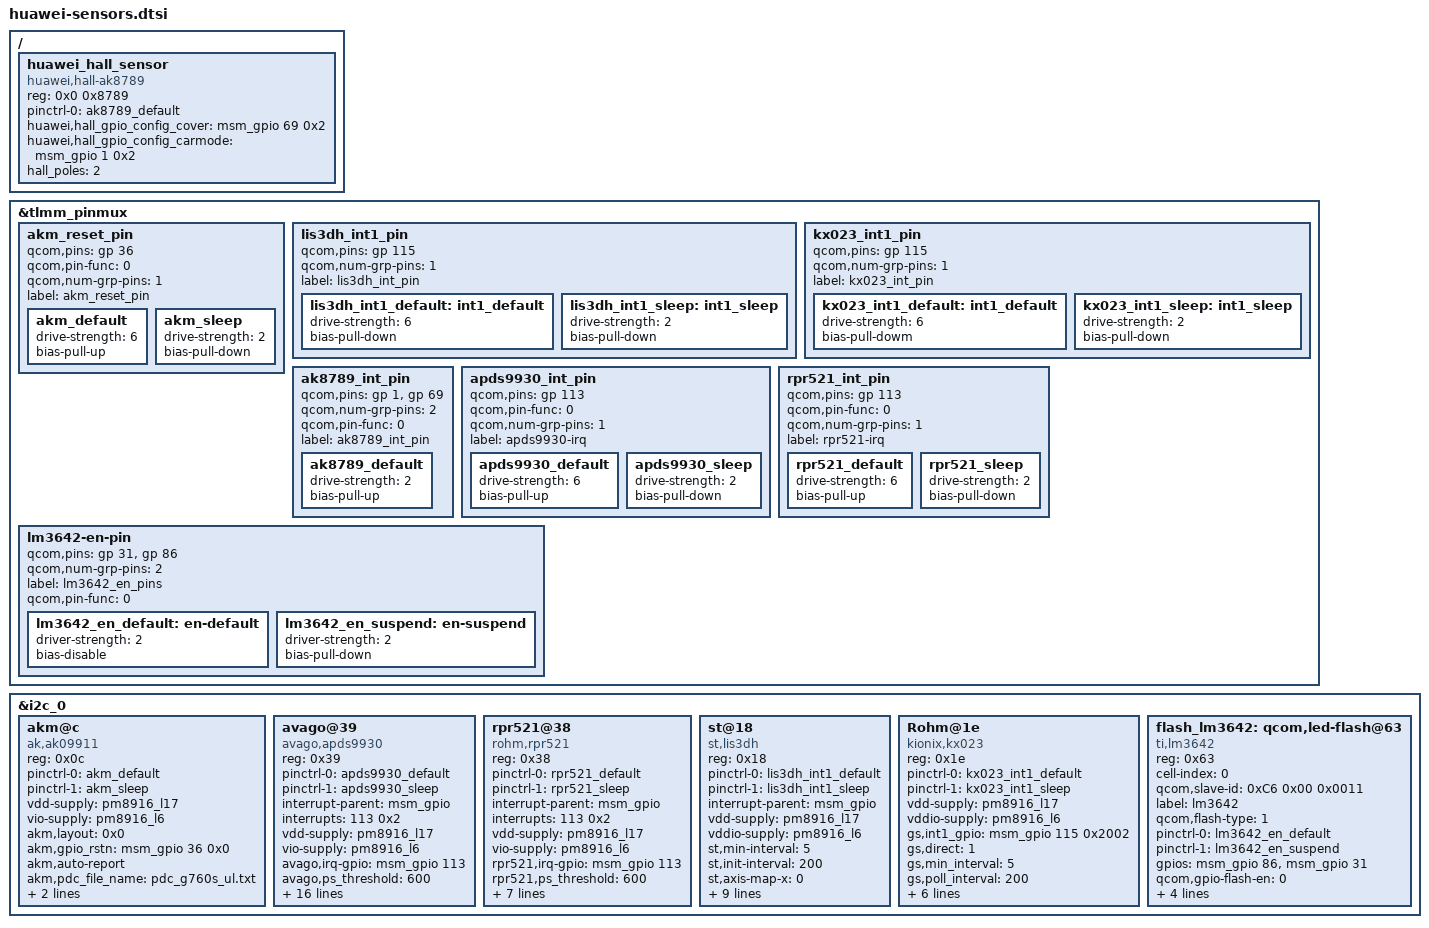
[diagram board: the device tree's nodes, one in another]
/*use fromdos convert file format to linux*/
/* Copyright (c) 2013 The Linux Foundation. All rights reserved.
 *
 * This program is free software; you can redistribute it and/or modify
 * it under the terms of the GNU General Public License version 2 and
 * only version 2 as published by the Free Software Foundation.
 *
 * This program is distributed in the hope that it will be useful,
 * but WITHOUT ANY WARRANTY; without even the implied warranty of
 * MERCHANTABILITY or FITNESS FOR A PARTICULAR PURPOSE.  See the
 * GNU General Public License for more details.
 */
&tlmm_pinmux {
	akm_reset_pin {
		qcom,pins = <&gp 36>;
		qcom,pin-func = <0>;
		qcom,num-grp-pins = <1>;
		label = "akm_reset_pin";
		akm_default: akm_default {
			drive-strength = <6>;
			bias-pull-up;
		};
		akm_sleep: akm_sleep {
			drive-strength = <2>;
			bias-pull-down;
		};
	};

	lis3dh_int1_pin {
		qcom,pins = <&gp 115>;
		qcom,num-grp-pins = <1>;
		label = "lis3dh_int_pin";
		lis3dh_int1_default: int1_default {
			drive-strength = <6>;
			bias-pull-down;
		};
		lis3dh_int1_sleep: int1_sleep {
			drive-strength = <2>;
			bias-pull-down;
		};
	};

	kx023_int1_pin {
		qcom,pins = <&gp 115>;
		qcom,num-grp-pins = <1>;
		label = "kx023_int_pin";
		kx023_int1_default: int1_default {
			  drive-strength = <6>;
			  bias-pull-dowm;
		};
		kx023_int1_sleep: int1_sleep {
			drive-strength = <2>;
			bias-pull-down;
		};
	};

	ak8789_int_pin {
		qcom,pins = <&gp 1>, <&gp 69>;
		qcom,num-grp-pins = <2>;
		qcom,pin-func = <0>;
		label = "ak8789_int_pin";
		ak8789_default: ak8789_default {
			  drive-strength = <2>;
			  bias-pull-up;
		};
	};
	apds9930_int_pin {
		qcom,pins = <&gp 113>;
		qcom,pin-func = <0>;
		qcom,num-grp-pins = <1>;
		label = "apds9930-irq";
		apds9930_default: apds9930_default {
			drive-strength = <6>;
			bias-pull-up;
		};
		apds9930_sleep: apds9930_sleep {
			drive-strength = <2>;
			bias-pull-down;
		};
	};
	rpr521_int_pin {
		qcom,pins = <&gp 113>;
		qcom,pin-func = <0>;
		qcom,num-grp-pins = <1>;
		label = "rpr521-irq";
		rpr521_default: rpr521_default {
			drive-strength = <6>;
			bias-pull-up;
		};
		rpr521_sleep: rpr521_sleep {
			drive-strength = <2>;
			bias-pull-down;
		};
	};
        lm3642-en-pin {
                qcom,pins = <&gp 31>, <&gp 86>;
                qcom,num-grp-pins = <2>;
                label = "lm3642_en_pins";
                qcom,pin-func = <0>;

                lm3642_en_default: en-default {
                        driver-strength = <2>;
                        bias-disable;
                };
                lm3642_en_suspend: en-suspend {
                        driver-strength = <2>;
                        bias-pull-down;
                };
        };
};

&i2c_0 { /* BLSP1 QUP2 */
	akm@c {
		compatible = "ak,ak09911";
		reg = <0x0c>;
		pinctrl-names = "default","sleep";
		pinctrl-0 = <&akm_default>;
		pinctrl-1 = <&akm_sleep>;
		vdd-supply = <&pm8916_l17>;
		vio-supply = <&pm8916_l6>;
		akm,layout = <0x0>;
		akm,gpio_rstn = <&msm_gpio 36 0x0>;
		akm,auto-report;
		akm,pdc_file_name = "pdc_g760s_ul.txt";
		akm,i2c-scl-gpio = <&msm_gpio 7 0x0>;
		akm,i2c-sda-gpio = <&msm_gpio 6 0x0>;
	};

	avago@39 {
		compatible = "avago,apds9930";
		reg = <0x39>;
		pinctrl-names = "default","sleep";
		pinctrl-0 = <&apds9930_default>;
		pinctrl-1 = <&apds9930_sleep>;
		interrupt-parent = <&msm_gpio>;
		interrupts = <113 0x2>;
		vdd-supply = <&pm8916_l17>;
		vio-supply = <&pm8916_l6>;
		avago,irq-gpio = <&msm_gpio 113 0x2>;
		avago,ps_threshold = <600>;
		avago,ps_hysteresis_threshold = <500>;
		avago,ps_pulse = <8>;
		avago,ps_pgain = <0>;
		/*sync the value of als_b\c\d\e\f with g760-ul and adjust zhe value of ga_a\c\d*/
		avago,als_B = <1860>;
		avago,als_C = <750>;
		avago,als_D = <1290>;
		avago,ga_value = <48>;
		avago,ga_a_value = <155>;
		avago,ga_c_value = <430>;
		avago,ga_d_value = <130>;
		avago,window = <160>;
		avago,wave = <45>;
		avago,ga_e_value = <220>;
		avago,ga_f_value = <43>;
		avago,i2c-scl-gpio = <&msm_gpio 7 0x0>;
		avago,i2c-sda-gpio = <&msm_gpio 6 0x0>;
	};
	rpr521@38 {
		compatible = "rohm,rpr521";
		reg = <0x38>;
		pinctrl-names = "default","sleep";
		pinctrl-0 = <&rpr521_default>;
		pinctrl-1 = <&rpr521_sleep>;
		interrupt-parent = <&msm_gpio>;
		interrupts = <113 0x2>;
		vdd-supply = <&pm8916_l17>;
		vio-supply = <&pm8916_l6>;
		rpr521,irq-gpio = <&msm_gpio 113 0x2>;
		rpr521,ps_threshold = <600>;
		rpr521,window = <52>;
		rpr521,wave = <37>;
		rpr521,data0_array = <9290 7711 2079 1810>; 
		rpr521,data1_array = <5303 4367 685 580>;   
		rpr521,judge_array = <1000 1422 1700 3100>;
		rpr521,i2c-scl-gpio = <&msm_gpio 7 0x0>;
		rpr521,i2c-sda-gpio = <&msm_gpio 6 0x0>;
	};

	st@18 {
		compatible = "st,lis3dh";
		reg = <0x18>;
		pinctrl-names = "lis3dh_default","lis3dh_sleep";
		pinctrl-0 = <&lis3dh_int1_default>;
		pinctrl-1 = <&lis3dh_int1_sleep>;
		interrupt-parent = <&msm_gpio>;
		vdd-supply = <&pm8916_l17>;
		vddio-supply = <&pm8916_l6>;
		st,min-interval = <5>;
		st,init-interval = <200>;
		st,axis-map-x = <0>;
		st,axis-map-y = <1>;
		st,axis-map-z = <2>;
		/*1 is bottom and others means top*/
		st,axis-map-bottom=<1>;
		st,g-range = <2>;
		st,gpio-int1 = <&msm_gpio 115 0x2002>;	
		/delete-property/st,negate-x;
		st,negate-z;
		st,negate-y;
		st,i2c-scl-gpio = <&msm_gpio 7 0x0>;
		st,i2c-sda-gpio = <&msm_gpio 6 0x0>;
	};
	Rohm@1e {
		compatible = "kionix,kx023";
		reg = <0x1e>;
		pinctrl-names = "kx023_default","kx023_sleep";
		pinctrl-0 = <&kx023_int1_default>;
		pinctrl-1 = <&kx023_int1_sleep>;
		vdd-supply = <&pm8916_l17>;
		vddio-supply = <&pm8916_l6>;
		gs,int1_gpio = <&msm_gpio 115 0x2002>;
		gs,direct = <1>;
		gs,min_interval = <5>;
		gs,poll_interval = <200>;
		gs,accel_direction = <1>;
		gs,accel_irq_use_drdy = <0>;
		gs,accel_g_range = <0>;
		gs,accel_res = <0>;
		gs,i2c-scl-gpio = <&msm_gpio 7 0x0>;
		gs,i2c-sda-gpio = <&msm_gpio 6 0x0>;
	};
        flash_lm3642:qcom,led-flash@63 {
                reg = <0x63>;
                cell-index = <0>;
                qcom,slave-id = <0xC6 0x00 0x0011>;
                compatible = "ti,lm3642";
                label = "lm3642";
                qcom,flash-type = <1>;
                pinctrl-names = "cam_flash_default","cam_flash_suspend";
                pinctrl-0 = <&lm3642_en_default>;
                pinctrl-1 = <&lm3642_en_suspend>;
                gpios = <&msm_gpio 86 0>,
                        <&msm_gpio 31 0>;
                qcom,gpio-flash-en = <0>;
                qcom,gpio-flash-now = <1>;
                qcom,gpio-req-tbl-num = <0 1>;
                qcom,gpio-req-tbl-flags = <0 0>;
                qcom,gpio-req-tbl-label = "FLASH_EN",
                        "FLASH_NOW";
        };
};
/{
	huawei_hall_sensor{
		compatible = "huawei,hall-ak8789";
		reg = <0x0 0x8789>;
		pinctrl-names = "default";
		pinctrl-0 = <&ak8789_default>;
		huawei,hall_gpio_config_cover = <&msm_gpio 69 0x2>;
		huawei,hall_gpio_config_carmode = <&msm_gpio 1 0x2>;
		hall_poles = <2>;
		status = "ok";
	};
};
